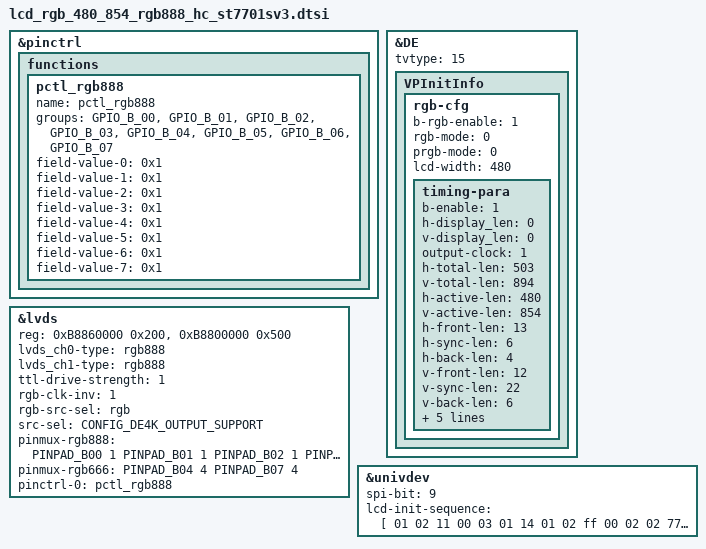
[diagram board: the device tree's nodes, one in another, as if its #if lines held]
&pinctrl {
	functions {
		pctl_rgb888: pctl_rgb888 {
			name = "pctl_rgb888";
			groups = "GPIO_B_00", "GPIO_B_01", "GPIO_B_02", "GPIO_B_03", "GPIO_B_04", "GPIO_B_05", "GPIO_B_06", "GPIO_B_07";
			field-value-0 = <0x1>;
			field-value-1 = <0x1>;
			field-value-2 = <0x1>;
			field-value-3 = <0x1>;
			field-value-4 = <0x1>;
			field-value-5 = <0x1>;
			field-value-6 = <0x1>;
			field-value-7 = <0x1>;
		};
	};
};

&lvds {
	reg = <0xB8860000 0x200>, <0xB8800000 0x500>;
	/*
	 * "lvds"		: LVDS screen
	 * "rgb888" 	: RGB screen
	 * "rgb666" 	: RGB screen
	 * "rgb565" 	: RGB screen
	 * "i2so"		: I2S OUT
	 * "gpio"		: only GPIO out
	 */
	lvds_ch0-type = "rgb888";
	lvds_ch1-type = "rgb888";

	/*
	 * 0: LVDS_TTL_DRIVE_STRENGTH_WEAKEST,
	 * 1: LVDS_TTL_DRIVE_STRENGTH_NORMAL,
	 * 2: LVDS_TTL_DRIVE_STRENGTH_ENHANCE,
	 * 3: LVDS_TTL_DRIVE_STRENGTH_STRONGEST,
	 */
	ttl-drive-strength = <1>;

	/*
	 *0 : RGB CLOCK NO INVERSION
	 *1 : RGB CLOCK INVERSION
	 */
	rgb-clk-inv = <1>;

	/*
	 * rgb gbr bgr
	 * rbg grb brg
	 */
	rgb-src-sel = "rgb";

	/*
	 * 0: E_SRC_SEL_FXDE = 0
	 * 1: E_SRC_SEL_4KDE = 1
	 * 2: E_SRC_SEL_HDMI_RX = 2
	 * 3: E_SRC_SEL_FXDE_ = 3
	 * 4: E_SRC_2_SEL_FXDE_LOW_TO_HIGH = 4 //need clsoe pq
	 * 5: E_SRC_2_SEL_DE4K_LOW_TO_HIGH = 5 //need clsoe pq
	 * 6: E_SRC_2_SEL_HDMI_RX_LOW_TO_HIGH = 6 //need clsoe pq
	 * 7: E_SRC_2_SEL_PQ_LOW_TO_HIGH = 7
	 */
	src-sel = <CONFIG_DE4K_OUTPUT_SUPPORT>;

	pinmux-rgb888 = <PINPAD_B00 1 PINPAD_B01 1 PINPAD_B02 1 PINPAD_B03 1 PINPAD_B04 1 PINPAD_B05 1 PINPAD_B06 1 PINPAD_B07 1>;/*RGB888 other pin set*/
	pinmux-rgb666 = <PINPAD_B04 4 PINPAD_B07 4>; /*RGB666 other pin set*/
	pinctrl-names = "rgb888";
	pinctrl-0 = <&pctl_rgb888>;
	// status = "okay";
};

&DE {
	tvtype = <15>;
	VPInitInfo {
		rgb-cfg{
			b-rgb-enable = <1>;
			/*
			 * 0: MODE_PRGB
			 * 1: MODE_SRGB
			 */
			rgb-mode = <0>;
			/*
			 * 0: MODE_PRGB_888_10bit
			 * 1: MODE_PRGB_666
			 */
			prgb-mode = <0>;
			lcd-width = <480>;
			timing-para {
				/* bool type, 0 or 1*/
				b-enable = <1>;

				h-display_len = <0>;
				v-display_len = <0>;

				/*
				 * VPO_RGB_CLOCK_27M = 1,
				 * VPO_RGB_CLOCK_33M = 2,
				 * VPO_RGB_CLOCK_49M = 3,
				 * VPO_RGB_CLOCK_66M = 4,
				 * VPO_RGB_CLOCK_74M = 5,
				 * VPO_RGB_CLOCK_85M = 6,
				 * VPO_RGB_CLOCK_108M = 7,
				 * VPO_RGB_CLOCK_6_6M = 8,
				 * VPO_RGB_CLOCK_9M = 9,
				 * VPO_RGB_CLOCK_39_6M = 10,
				 * VPO_RGB_CLOCK_74_25M = 11,
				 * VPO_RGB_CLOCK_148_5M = 12,
				 * VPO_RGB_CLOCK_54M = 13,
				 * VPO_RGB_CLOCK_132M = 14,//H1600
				 * VPO_RGB_CLOCK_297M = 15,//H1600 only De4k
				 * VPO_RGB_CLOCK_DPLL = 0xFF,//H1600
				*/
				output-clock = <1>;

				h-total-len = <503>;
				v-total-len = <894>;

				h-active-len = <480>;
				v-active-len = <854>;

				h-front-len = <13>;
				h-sync-len = <6>;
				h-back-len = <4>;

				v-front-len = <12>;
				v-sync-len = <22>;
				v-back-len = <6>;

				/* bool type, 0 or 1*/
				h-sync-level = <0>;
				/* bool type, 0 or 1*/
				v-sync-level = <0>;

				/* bool type, 0 or 1*/
				active-polarity = <1>;
				frame-rate = <60000>;

				/*
				31	De_dig_pll_en
				25:16	DE_DIG_PLL_M_ctrl
				13:8	DE_DIG_PLL_N_ctrl
				5:0	DE_DIG_PLL_L_ctrl
				de_digpll_clock = 24 *(M+1)/((N+1)*(L+1))
				*/
				dpll-clock-reg-value = <0x0>;
			};
		};
	};
};

#ifdef LCD_UNIVDEV_ENABLED
&univdev{
	spi-bit = <9>;
	lcd-init-sequence = [
		01 02 11 00
		03 01 14
		01 02 ff 00
		02 02 77 01
		02 02 01 01
		02 02 00 01
		02 02 00 01
		02 02 10 01
		01 02 c0 00
		02 02 e9 01
		02 02 03 01
		01 02 c1 00
		02 02 11 01
		02 02 02 01
		01 02 c2 00
		02 02 31 01
		02 02 08 01
		01 02 cc 00
		02 02 10 01
		01 02 b0 00
		02 02 00 01
		02 02 06 01
		02 02 11 01
		02 02 12 01
		02 02 18 01
		02 02 0a 01
		02 02 0a 01
		02 02 09 01
		02 02 09 01
		02 02 1d 01
		02 02 09 01
		02 02 14 01
		02 02 10 01
		02 02 0e 01
		02 02 11 01
		02 02 19 01
		01 02 b1 00
		02 02 00 01
		02 02 06 01
		02 02 11 01
		02 02 11 01
		02 02 15 01
		02 02 09 01
		02 02 0b 01
		02 02 09 01
		02 02 09 01
		02 02 23 01
		02 02 09 01
		02 02 17 01
		02 02 14 01
		02 02 18 01
		02 02 1e 01
		02 02 19 01
		01 02 ff 00
		02 02 77 01
		02 02 01 01
		02 02 00 01
		02 02 00 01
		02 02 11 01
		01 02 b0 00
		02 02 4d 01
		01 02 b1 00
		02 02 3a 01
		01 02 b2 00
		02 02 07 01
		01 02 b3 00
		02 02 80 01
		01 02 b5 00
		02 02 47 01
		01 02 b7 00
		02 02 85 01
		01 02 b8 00
		02 02 21 01
		01 02 b9 00
		02 02 10 01
		01 02 c1 00
		02 02 78 01
		01 02 c2 00
		02 02 78 01
		01 02 d0 00
		02 02 88 01
		03 01 64
		01 02 e0 00
		02 02 00 01
		02 02 00 01
		02 02 02 01
		01 02 e1 00
		02 02 08 01
		02 02 00 01
		02 02 0a 01
		02 02 00 01
		02 02 07 01
		02 02 00 01
		02 02 09 01
		02 02 00 01
		02 02 00 01
		02 02 33 01
		02 02 33 01
		01 02 e2 00
		02 02 00 01
		02 02 00 01
		02 02 00 01
		02 02 00 01
		02 02 00 01
		02 02 00 01
		02 02 00 01
		02 02 00 01
		02 02 00 01
		02 02 00 01
		02 02 00 01
		02 02 00 01
		02 02 00 01
		01 02 e3 00
		02 02 00 01
		02 02 00 01
		02 02 33 01
		02 02 33 01
		01 02 e4 00
		02 02 44 01
		02 02 44 01
		01 02 e5 00
		02 02 0e 01
		02 02 60 01
		02 02 af 01
		02 02 af 01
		02 02 10 01
		02 02 60 01
		02 02 af 01
		02 02 af 01
		02 02 0a 01
		02 02 60 01
		02 02 af 01
		02 02 af 01
		02 02 0c 01
		02 02 60 01
		02 02 af 01
		02 02 af 01
		01 02 e6 00
		02 02 00 01
		02 02 00 01
		02 02 33 01
		02 02 33 01
		01 02 e7 00
		02 02 44 01
		02 02 44 01
		01 02 e8 00
		02 02 0d 01
		02 02 60 01
		02 02 af 01
		02 02 af 01
		02 02 0f 01
		02 02 60 01
		02 02 af 01
		02 02 af 01
		02 02 09 01
		02 02 60 01
		02 02 af 01
		02 02 af 01
		02 02 0b 01
		02 02 60 01
		02 02 af 01
		02 02 af 01
		01 02 eb 00
		02 02 02 01
		02 02 01 01
		02 02 e4 01
		02 02 e4 01
		02 02 44 01
		02 02 00 01
		02 02 40 01
		01 02 ec 00
		02 02 02 01
		02 02 01 01
		01 02 ed 00
		02 02 ab 01
		02 02 89 01
		02 02 76 01
		02 02 54 01
		02 02 01 01
		02 02 ff 01
		02 02 ff 01
		02 02 ff 01
		02 02 ff 01
		02 02 ff 01
		02 02 ff 01
		02 02 10 01
		02 02 45 01
		02 02 67 01
		02 02 98 01
		02 02 ba 01
		01 02 3a 00
		02 02 77 01
		01 02 36 00
		02 02 00 01
		01 02 ff 00
		02 02 77 01
		02 02 01 01
		02 02 00 01
		02 02 00 01
		02 02 00 01
		01 02 29 00
	];
};
#endif
